AUTOSAR XML (schema 4-3-0)
package /e/s1
  client server interface i1
  sender receiver interface i2
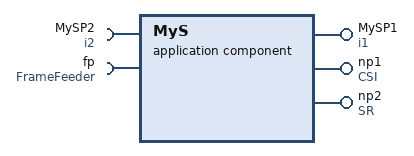
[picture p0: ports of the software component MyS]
  application sw component type MyS
    provide port MySP1: provided-interface=i1
    require port MySP2: required-interface=i2
    provide port np1: provided-interface=CSI
    provide port np2: provided-interface=SR
    require port fp: required-interface=FrameFeeder
package /m1
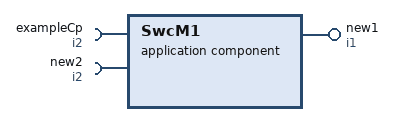
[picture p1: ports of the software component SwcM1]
  application sw component type SwcM1
    require port exampleCp: required-interface=i2, qwe=rty=uio=val
    provide port new1: provided-interface=i1
    require port new2: required-interface=i2
package /newPackage/p1/p2/p3
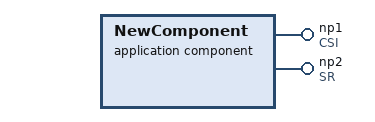
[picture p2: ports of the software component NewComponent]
  application sw component type NewComponent
    provide port np1: provided-interface=CSI
    provide port np2: provided-interface=SR
